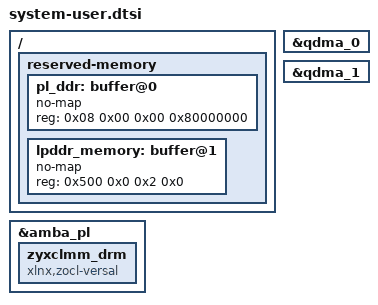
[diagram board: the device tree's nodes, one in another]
/include/ "system-conf.dtsi"
/ {
	reserved-memory {
		#address-cells = <2>;
		#size-cells = <2>;
		ranges;
		pl_ddr: buffer@0 {
			no-map;
			reg = <0x08 0x00 0x00 0x80000000>;
		};
		lpddr_memory: buffer@1 {
			no-map;
			reg = <0x500 0x0 0x2 0x0>;
		};
	};
};

&amba_pl {
	zyxclmm_drm {
		compatible = "xlnx,zocl-versal";
	};
};

/* QDMA DT override per AMD AR76647 "no-patch" recipe for 2024.2+.
 * Requires Vivado: CONFIG.axibar_notranslate {true} on both qdmas,
 * CONFIG.pf0_bar0_size_qdma {16} (or >=64 GB). Identity-maps both M32
 * and M64 ranges so Linux has the proper CPU↔PCI address spaces for
 * endpoint BAR allocation. No BDF patch or Fidus 2 GiB DMA workaround
 * needed with this setup. */
&qdma_0 {
	ranges = <0x02000000 0x00 0xA8000000 0x00 0xA8000000 0x00 0x04000000>,
	         <0x43000000 0x04 0x80000000 0x04 0x80000000 0x00 0x40000000>;
};

&qdma_1 {
	ranges = <0x02000000 0x00 0xAC000000 0x00 0xAC000000 0x00 0x04000000>,
	         <0x43000000 0x04 0xC0000000 0x04 0xC0000000 0x00 0x40000000>;
};
